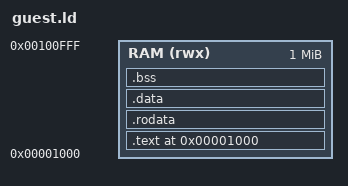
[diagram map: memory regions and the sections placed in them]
ENTRY(_start)

MEMORY {
  RAM (rwx) : ORIGIN = 0x1000, LENGTH = 0x00100000
}

SECTIONS {
  . = 0x1000;
  .text : {
    *(.text._start)
    *(.text .text.*)
  } > RAM
  .rodata : { *(.rodata .rodata.*) } > RAM
  .data : { *(.data .data.*) } > RAM
  .bss (NOLOAD) : { *(.bss .bss.*) *(COMMON) } > RAM
  . = ALIGN(4);
  . = . + 0x10000; /* 64 KiB stack */
  __stack_top = .;
  /DISCARD/ : { *(.comment) *(.eh_frame*) *(.riscv.attributes) *(.note*) }
}
